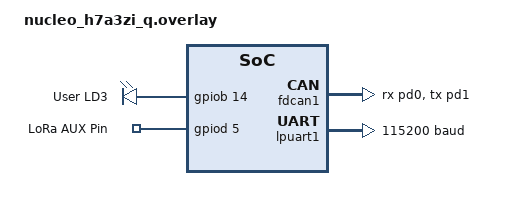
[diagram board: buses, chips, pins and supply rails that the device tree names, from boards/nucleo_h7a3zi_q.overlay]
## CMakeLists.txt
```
cmake_minimum_required(VERSION 3.20.0)

set(DTC_OVERLAY_FILE 
    "${CMAKE_CURRENT_LIST_DIR}/app.overlay"
    "${CMAKE_CURRENT_LIST_DIR}/boards/${BOARD}.overlay"
)

find_package(Zephyr REQUIRED HINTS $ENV{ZEPHYR_BASE})

project(deos_firmware)


target_sources(app PRIVATE
    src/main.cpp
    src/MainApp.cpp
    src/io/LedController.cpp
    src/io/SafetyManager.cpp
    src/io/ImuSensor.cpp
    src/network/NetworkMonitor.cpp
    src/transport/eth_textual.cpp
    src/transport/eth_ros_bridge.cpp
    src/transport/uart_lora.cpp
    ../../lib/deos_core/src/deos_core.c
    ../../lib/deos_core/src/deos_rx.c
    ../../lib/deos_core/src/deos_tx.c
    ../../lib/deos_core/src/deos_dispatch.c
    ../../lib/deos_core/src/deos_codec.c
    ../../lib/deos_core/src/deos_network.c
    ../../lib/deos_core/src/deos_router.c
    ../../lib/deos_core/src/deos_fault.c
)

zephyr_include_directories(../../lib/deos_core/include)

# Disable thread-safe statics for C++ to prevent __cxa_guard_* linker errors
target_compile_options(app PRIVATE $<$<COMPILE_LANGUAGE:CXX>:-fno-threadsafe-statics>)

# Disable thread-safe statics for C++ to prevent __cxa_guard_* linker errors
target_compile_options(app PRIVATE $<$<COMPILE_LANGUAGE:CXX>:-fno-threadsafe-statics>)
```

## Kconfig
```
source "Kconfig.zephyr"

rsource "../../lib/deos_core/Kconfig"
```

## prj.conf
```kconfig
# ============================================================
# Zephyr Project Configuration
# ============================================================

# Console / printk
CONFIG_PRINTK=y

# Assertions
CONFIG_ASSERT=y

# Logging
CONFIG_LOG=y
CONFIG_LOG_DEFAULT_LEVEL=3

# Main thread stack
CONFIG_MAIN_STACK_SIZE=2048

# ------------------------------------------------------------
# Add project-specific configuration below
# ------------------------------------------------------------

# ---------------------------------------------------------
# DEOS Core Prototype
# ---------------------------------------------------------

CONFIG_LOG=y
CONFIG_LOG_DEFAULT_LEVEL=3

# CAN desteği
CONFIG_CAN=y
CONFIG_CAN_FD_MODE=y

# ---------------------------------------------------------
# DEOS Core Configuration (Optional overrides)
# ---------------------------------------------------------
# CONFIG_DEOS_MAX_LOCAL_NODES=4
# CONFIG_DEOS_MAX_FAULT_RECORDS=32
# CONFIG_DEOS_MAX_HANDLERS=32
# CONFIG_DEOS_RX_QUEUE_SIZE=16
# CONFIG_DEOS_RX_THREAD_STACK_SIZE=1024
# CONFIG_DEOS_RX_THREAD_PRIORITY=5

# ---------------------------------------------------------
# LoRa UART & GPIO settings
# ---------------------------------------------------------
CONFIG_SERIAL=y
CONFIG_UART_INTERRUPT_DRIVEN=y
CONFIG_GPIO=y

# ---------------------------------------------------------
# CRC Support for LoRa
# ---------------------------------------------------------
CONFIG_CRC=y

# ---------------------------------------------------------
# Networking / Ethernet / TCP Sockets
# ---------------------------------------------------------
CONFIG_NETWORKING=y
CONFIG_NET_IPV4=y
CONFIG_NET_TCP=y
CONFIG_NET_UDP=y
CONFIG_NET_SOCKETS=y
# Maksimum bağlantı ve soket ayarları
CONFIG_NET_MAX_CONN=4
CONFIG_NET_MAX_CONTEXTS=4

# İsteğe bağlı Statik IP ayarı (Eğer DHCP yoksa)
# RPi tarafı ile aynı ağda (örn: 192.168.1.x) olmalıdır
CONFIG_NET_CONFIG_SETTINGS=y
CONFIG_NET_CONFIG_MY_IPV4_ADDR="192.168.1.10"
CONFIG_NET_CONFIG_PEER_IPV4_ADDR="192.168.1.1"

# Ethernet kablosu takılı değilse veya link gecikirse Zephyr'in bootta beklemesini engelle
CONFIG_NET_CONFIG_INIT_TIMEOUT=0
# ---------------------------------------------------------
# C++ Support
# ---------------------------------------------------------
CONFIG_CPP=y
CONFIG_STD_CPP17=y

# ---------------------------------------------------------
# micro-ROS Configuration (REMOVED)
# ---------------------------------------------------------
CONFIG_PICOLIBC=n
CONFIG_NEWLIB_LIBC=y

CONFIG_POSIX_API=y
```

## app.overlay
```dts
/*
 * ==============================================================================
 * ANA UYGULAMA OVERLAY DOSYASI (app.overlay)
 * ==============================================================================
 * Amacı: Bu dosya, uygulamanın donanımdan bağımsız "iskelet" yapısını kurar.
 * Hangi karta derlenirse derlensin her zaman geçerli olan ortak ayarları içerir.
 * Fiziksel pin atamaları BURADA YAPILMAZ! Pin atamaları 'boards/' klasöründeki
 * karta özel overlay dosyalarında yapılır.
 * ==============================================================================
 */

/ {
    chosen {
        zephyr,can-primary = &fdcan1;
    };
};

/* Enable Primary CAN (FDCAN1) */
&fdcan1 {
    status = "okay";
    bus-speed = <500000>;
    bus-speed-data = <2000000>;
};
```

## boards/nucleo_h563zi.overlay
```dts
/*
 * ==============================================================================
 * KARTA ÖZEL OVERLAY DOSYASI (boards/nucleo_h563zi.overlay)
 * ==============================================================================
 * Hedef Kart: NUCLEO-H563ZI (STM32H5)
 * Amacı: app.overlay dosyasında tanımlanan iskeletin (node ve alias'ların),
 * bu spesifik karta ait fiziksel pinlere ve donanımlara (UART, GPIO vb.) 
 * nasıl bağlanacağını (kablolanacağını) belirler.
 * ==============================================================================
 */

/ {
    aliases {
        lora-uart = &lpuart1;
        led2 = &red_led_1;
    };
};

/* CAN-FD Physical Pin Mapping */
&fdcan1 {
    pinctrl-0 = <&fdcan1_rx_pd0 &fdcan1_tx_pd1>;
    pinctrl-names = "default";
};

/* LoRa UART Physical Pin Mapping */
&lpuart1 {
    status = "okay";
    current-speed = <115200>;
    /* Note: H5 varsayılan olarak PB6(TX) ve PB7(RX) pinlerini kullanır */
};

/* LoRa AUX Physical Pin Mapping */
/ {
    lora_module {
        compatible = "gpio-keys";
        lora_aux: lora_aux {
            gpios = <&gpioe 14 GPIO_ACTIVE_HIGH>;
            label = "LoRa AUX Pin";
        };
    };
};
```

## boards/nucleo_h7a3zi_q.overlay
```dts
/*
 * ==============================================================================
 * KARTA ÖZEL OVERLAY DOSYASI (boards/nucleo_h7a3zi_q.overlay)
 * ==============================================================================
 * Hedef Kart: NUCLEO-H7A3ZI-Q (STM32H7)
 * Amacı: app.overlay dosyasında tanımlanan iskeletin (node ve alias'ların),
 * bu spesifik karta ait fiziksel pinlere ve donanımlara (UART, GPIO vb.) 
 * nasıl bağlanacağını (kablolanacağını) belirler.
 * ==============================================================================
 */

/ {
    aliases {
        lora-uart = &lpuart1;
        led2 = &my_red_led;
    };

    leds {
        compatible = "gpio-leds";
        my_red_led: led_2 {
            gpios = <&gpiob 14 GPIO_ACTIVE_HIGH>;
            label = "User LD3";
        };
    };
};

/* CAN-FD Physical Pin Mapping */
&fdcan1 {
    pinctrl-0 = <&fdcan1_rx_pd0 &fdcan1_tx_pd1>;
    pinctrl-names = "default";
};



/* LoRa UART Physical Pin Mapping */
&lpuart1 {
    status = "okay";
    current-speed = <115200>;
};

/* LoRa AUX Physical Pin Mapping */
/ {
    lora_module {
        compatible = "gpio-keys";
        lora_aux: lora_aux {
            gpios = <&gpiod 5 GPIO_ACTIVE_HIGH>;
            label = "LoRa AUX Pin";
        };
    };
};

&timers12 {
    status = "disabled";
};
```

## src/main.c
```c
#include <zephyr/kernel.h>
#include <zephyr/logging/log.h>
#include <deos/deos.h>
#include <deos/deos_fault.h>

#include "eth_textual.h"
#include "eth_uros.h"
#include "uart_lora.h"

LOG_MODULE_REGISTER(main_node, LOG_LEVEL_INF);

/* Application defined routing policy */
static deos_transport_t main_routing_policy(deos_node_id_t destination)
{
    if (destination == DEOS_NODE_TEXTUAL) {
        return DEOS_TRANSPORT_ETH_TEXTUAL;
    }
    if (destination == DEOS_NODE_MICRO_ROS) {
        return DEOS_TRANSPORT_ETH_UROS;
    }
    if (destination == DEOS_NODE_GROUND_CONTROL) {
        return DEOS_TRANSPORT_UART_LORA;
    }
    
    /* Route everything else to the CAN-FD network by default */
    return DEOS_TRANSPORT_CAN_FD;
}

int main(void)
{
    LOG_INF("Starting DEOS Main STM32 Gateway...");

    /* Initialize DEOS Configuration */
    struct deos_config config = {
        .node_id = DEOS_NODE_MAIN_STM32,
        .can_dev = DEVICE_DT_GET(DT_CHOSEN(zephyr_can_primary)),
        .router_enabled = true,
        .hosted_nodes_enabled = true
    };

    if (!device_is_ready(config.can_dev)) {
        LOG_ERR("CAN device not ready");
        return -1;
    }

    /* Set our custom routing lookup function */
    deos_router_set_lookup_fn(main_routing_policy);

    /* Initialize DEOS Core */
    int ret = deos_init(&config);
    if (ret != 0) {
        LOG_ERR("DEOS init failed: %d", ret);
        return ret;
    }

    /* Initialize External Ethernet Interfaces */
    eth_textual_init();
    eth_uros_init(); /* TODO: Implement micro-ROS */
    uart_lora_init();

    /* Start DEOS threads */
    deos_start();

    while (1) {
        k_sleep(K_MSEC(1000));
        /* Main application background tasks */
    }

    return 0;
}
```

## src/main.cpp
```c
#include "MainApp.hpp"

int main(void)
{
    if (MainApp::getInstance().init() == 0) {
        MainApp::getInstance().run();
    }
    return 0;
}
```

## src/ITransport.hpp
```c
#pragma once

#include <deos/deos.h>

class ITransport {
public:
    virtual ~ITransport() = default;
    
    /**
     * @brief Initialize the transport.
     * @return 0 on success, negative error code on failure.
     */
    virtual int init() = 0;
    
    /**
     * @brief Send a message over the transport.
     * @param msg Pointer to the DEOS message to send.
     * @return 0 on success, negative error code on failure.
     */
    virtual int send(const deos_message_t* msg) = 0;
};
```

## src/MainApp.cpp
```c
#include "MainApp.hpp"
#include "transport/eth_textual.hpp"
#include "transport/eth_ros_bridge.hpp"
#include "transport/uart_lora.hpp"
#include "io/ImuSensor.hpp"
#include <zephyr/logging/log.h>

LOG_MODULE_REGISTER(main_node_app, LOG_LEVEL_INF);

MainApp& MainApp::getInstance() {
    static MainApp instance;
    return instance;
}

static const char* state_to_str(deos_state_t s) {
    switch(s) {
        case DEOS_STATE_INIT: return "INIT (0x00)";
        case DEOS_STATE_STANDBY: return "STANDBY (0x01)";
        case DEOS_STATE_READY: return "READY (0x02)";
        case DEOS_STATE_ACTIVE: return "ACTIVE (0x03)";
        case DEOS_STATE_CALIBRATING: return "CALIBRATING (0x04)";
        case DEOS_STATE_SAFE: return "SAFE (0x05)";
        case DEOS_STATE_FAULT: return "FAULT (0x06)";
        default: return "UNKNOWN";
    }
}

extern "C" {
    int heartbeat_rx_callback(const deos_message_t *msg, void *user_data) {
        MainApp& app = MainApp::getInstance();
        
        deos_state_t reported_state = DEOS_STATE_UNKNOWN;
        if (msg->payload_len == sizeof(struct deos_heartbeat_payload)) {
            const struct deos_heartbeat_payload *pl = (const struct deos_heartbeat_payload *)msg->payload;
            reported_state = (deos_state_t)pl->current_state;
        }
        
        app.network_monitor.update_heartbeat(msg->source, reported_state, app.current_state);
        return 0;
    }

    int set_state_rx_callback(const deos_message_t *msg, void *user_data) {
        MainApp& app = MainApp::getInstance();
        
        if (msg->payload_len == 1) {
            deos_state_t req_state = (deos_state_t)msg->payload[0];
            LOG_INF("Received SET_STATE command from Node 0x%02X: requesting state %s", msg->source, state_to_str(req_state));
            app.set_state(req_state);
            deos_send_response(msg, DEOS_RESULT_SUCCESS, NULL, 0);
        } else {
            LOG_WRN("Invalid SET_STATE payload length: %d", msg->payload_len);
            deos_send_response(msg, DEOS_RESULT_INVALID_PARAMETER, NULL, 0);
        }
        return 0;
    }

    deos_transport_t c_routing_policy(deos_node_id_t destination) {
        if (destination == DEOS_NODE_GROUND_CONTROL) {
            return DEOS_TRANSPORT_UART_LORA;
        } else if (destination == DEOS_NODE_MICRO_ROS) {
            return DEOS_TRANSPORT_ETH_UROS;
        } else if (destination == DEOS_NODE_DIAG_TOOL) {
            return DEOS_TRANSPORT_ETH_TEXTUAL;
        }
        /* UART/LoRa testleri esnasinda CAN FD'ye gonderip sistemi kitlememesi icin kapali */
        /*
        else if (destination >= DEOS_NODE_TRACTION && destination <= DEOS_NODE_BMS_GATEWAY) {
            return DEOS_TRANSPORT_CAN_FD;
        }
        */
        return DEOS_TRANSPORT_LOCAL;
    }
}

int MainApp::init() {
    int ret = led_controller.init();
    if (ret != 0) return ret;

    ret = safety_manager.init();
    if (ret != 0) return ret;

    struct deos_config config = {
        .node_id = DEOS_NODE_MAIN_STM32,
        .can_dev = DEVICE_DT_GET(DT_CHOSEN(zephyr_can_primary)),
        .router_enabled = true,
        .hosted_nodes_enabled = true
    };

    if (!device_is_ready(config.can_dev)) {
        LOG_ERR("CAN device not ready");
        return -ENODEV;
    }

    ret = deos_init(&config);
    if (ret != 0) {
        LOG_ERR("DEOS init failed: %d", ret);
        return ret;
    }

    deos_router_set_lookup_fn(c_routing_policy);
    
    /* DEOS çekirdeğine Heartbeat paketlerini nereye düşüreceğini söylüyoruz */
    deos_register_handler(DEOS_CLASS_NETWORK, DEOS_SERVICE_SYSTEM, DEOS_CMD_SYSTEM_HEARTBEAT, heartbeat_rx_callback, NULL);

    /* SET_STATE komutunu (Cmd: 0x02, Class: COMMAND) dinle */
    deos_register_handler(DEOS_CLASS_COMMAND, DEOS_SERVICE_SYSTEM, DEOS_CMD_SYSTEM_SET_STATE, set_state_rx_callback, NULL);

    EthTextual::getInstance().init();
    EthRosBridge::getInstance().init();
    UartLora::getInstance().init();
    ImuSensor::getInstance().init();

    return 0;
}

void MainApp::set_state(deos_state_t new_state) {
    if (current_state == new_state) return;

    current_state = new_state;

    /* Durum değiştiğinde ağdaki tüm nodlara bildir (Broadcast) */
    deos_priority_t prio = (new_state == DEOS_STATE_SAFE || new_state == DEOS_STATE_FAULT) 
                            ? DEOS_PRIO_EMERGENCY : DEOS_PRIO_CONTROL;

    deos_send(DEOS_NODE_GLOBAL_BROADCAST, prio, DEOS_CLASS_COMMAND, DEOS_SERVICE_SYSTEM, 
              DEOS_CMD_SYSTEM_SET_STATE, &current_state, sizeof(current_state));

    LOG_INF("System State changed to: %s", state_to_str(current_state));
}

void MainApp::run() {
    deos_start();

    LOG_INF("Main System Controller (Brain) loop started.");

    /* Sistemi hazır (STANDBY) moduna geçir */
    set_state(DEOS_STATE_STANDBY);
    
    uint32_t ms_counter = 0;
    bool last_estop_state = safety_manager.is_estop_triggered();

    while (1) {
        bool estop_pressed = safety_manager.is_estop_triggered();

        /* --- DONANIMSAL KESME / GÜVENLİK KONTROLÜ (EDGE DETECTION) --- */
        if (estop_pressed && !last_estop_state) {
            LOG_ERR("!!! EMERGENCY STOP TRIGGERED !!!");
            set_state(DEOS_STATE_SAFE);
        } else if (!estop_pressed && last_estop_state) {
            LOG_INF("E-STOP Released.");
            set_state(DEOS_STATE_STANDBY);
        }
        
        last_estop_state = estop_pressed;

        /* --- NETWORK (NODE) WATCHDOG & HEARTBEAT --- */
        network_monitor.check_watchdog(*this);
        network_monitor.broadcast_heartbeat(current_state, ms_counter);

        /* --- STATE MACHINE (DURUM MAKİNESİ) Görselleri --- */
        led_controller.update(current_state, ms_counter);

        ms_counter += 10;
        k_sleep(K_MSEC(10));
    }
}
```

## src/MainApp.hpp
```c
#pragma once

#include <deos/deos.h>

class MainApp {
public:
    static MainApp& getInstance();
    
    int init();
    void run();

private:
    MainApp() = default;
    ~MainApp() = default;

    // Non-copyable
    MainApp(const MainApp&) = delete;
    MainApp& operator=(const MainApp&) = delete;

    static deos_transport_t routing_policy(deos_node_id_t destination);
};
```

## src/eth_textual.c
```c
#include <zephyr/kernel.h>
#include <zephyr/logging/log.h>
#include <zephyr/net/socket.h>
#include <deos/deos.h>
#include <deos/deos_fault.h>
#include "eth_textual.h"

LOG_MODULE_REGISTER(eth_textual, LOG_LEVEL_INF);

#define TEXTUAL_TX_QUEUE_SIZE 16
#define TEXTUAL_THREAD_STACK_SIZE 2048
#define TEXTUAL_THREAD_PRIO 5
#define TEXTUAL_TCP_PORT 5000

/* TX Queue to prevent blocking the router */
K_MSGQ_DEFINE(textual_tx_q, sizeof(deos_message_t), TEXTUAL_TX_QUEUE_SIZE, 4);

/* Threads */
static struct k_thread textual_server_thread_data;
static K_KERNEL_STACK_DEFINE(textual_server_stack, TEXTUAL_THREAD_STACK_SIZE);

static struct k_thread textual_tx_thread_data;
static K_KERNEL_STACK_DEFINE(textual_tx_stack, TEXTUAL_THREAD_STACK_SIZE);

/* Global client socket to allow TX thread to send data */
static int active_client_sock = -1;

/* Router TX callback */
static int textual_tx_callback(const deos_message_t *msg)
{
    /* If no client connected, just drop silently or log debug */
    if (active_client_sock < 0) {
        return -ENOTCONN;
    }

    /* Push to queue, do not block the router */
    if (k_msgq_put(&textual_tx_q, msg, K_NO_WAIT) != 0) {
        LOG_WRN("Textual TX queue full, dropping message");
        deos_fault_raise(DEOS_FAULT_TX_FAILURE, DEOS_FAULT_SEVERITY_WARNING);
        return -ENOSPC;
    }
    return 0;
}

/* TX Thread (Sends data out over TCP) */
static void textual_tx_thread(void *p1, void *p2, void *p3)
{
    deos_message_t msg;
    LOG_INF("Textual TCP TX Thread started");

    while (1) {
        if (k_msgq_get(&textual_tx_q, &msg, K_FOREVER) == 0) {
            if (active_client_sock >= 0) {
                /* Serialize to dynamic frame size */
                size_t header_sz = offsetof(deos_message_t, payload);
                uint8_t len = header_sz + msg.payload_len;
                
                uint8_t tx_buf[DEOS_MAX_PAYLOAD_LEN + 30];
                tx_buf[0] = len; /* 1 Byte Length */
                memcpy(&tx_buf[1], &msg, header_sz);
                if (msg.payload_len > 0) {
                    memcpy(&tx_buf[1 + header_sz], msg.payload, msg.payload_len);
                }

                /* Send over TCP */
                int sent = send(active_client_sock, tx_buf, len + 1, 0);
                if (sent < 0) {
                    LOG_ERR("TCP Send failed (%d), dropping client", errno);
                    close(active_client_sock);
                    active_client_sock = -1;
                }
            }
        }
    }
}

/* Server Thread (Listens for TCP and Receives data) */
static void textual_server_thread(void *p1, void *p2, void *p3)
{
    int serv_sock;
    struct sockaddr_in bind_addr;

    serv_sock = socket(AF_INET, SOCK_STREAM, IPPROTO_TCP);
    if (serv_sock < 0) {
        LOG_ERR("Failed to create TCP socket: %d", errno);
        return;
    }

    bind_addr.sin_family = AF_INET;
    bind_addr.sin_addr.s_addr = htonl(INADDR_ANY);
    bind_addr.sin_port = htons(TEXTUAL_TCP_PORT);

    if (bind(serv_sock, (struct sockaddr *)&bind_addr, sizeof(bind_addr)) < 0) {
        LOG_ERR("Failed to bind TCP socket: %d", errno);
        close(serv_sock);
        return;
    }

    if (listen(serv_sock, 1) < 0) {
        LOG_ERR("Failed to listen on TCP socket: %d", errno);
        close(serv_sock);
        return;
    }

    LOG_INF("Textual TCP Server listening on port %d", TEXTUAL_TCP_PORT);

    while (1) {
        struct sockaddr_in client_addr;
        socklen_t client_addr_len = sizeof(client_addr);
        
        LOG_INF("Waiting for Textual UI connection...");
        int client = accept(serv_sock, (struct sockaddr *)&client_addr, &client_addr_len);
        
        if (client < 0) {
            LOG_ERR("Accept failed: %d", errno);
            k_msleep(1000);
            continue;
        }

        LOG_INF("Textual UI Connected!");
        active_client_sock = client;

        while (1) {
            uint8_t rx_len;
            int ret = recv(client, &rx_len, 1, 0);
            if (ret <= 0) {
                LOG_INF("Textual UI Disconnected.");
                break;
            }

            /* Prevent buffer overflows */
            if (rx_len == 0 || rx_len > sizeof(deos_message_t)) {
                LOG_WRN("Invalid frame length %d received, closing connection.", rx_len);
                break;
            }

            uint8_t frame_buf[sizeof(deos_message_t)];
            int received = 0;
            
            /* Read exactly rx_len bytes for the frame */
            while (received < rx_len) {
                ret = recv(client, frame_buf + received, rx_len - received, 0);
                if (ret <= 0) break;
                received += ret;
            }

            if (received != rx_len) {
                LOG_WRN("Incomplete frame received.");
                break;
            }

            /* Successfully received full DEOS dynamic frame */
            size_t header_sz = offsetof(deos_message_t, payload);
            if (rx_len >= header_sz) {
                deos_message_t msg;
                memset(&msg, 0, sizeof(msg));
                memcpy(&msg, frame_buf, header_sz);
                msg.payload_len = rx_len - header_sz;
                
                if (msg.payload_len > 0) {
                    memcpy(msg.payload, frame_buf + header_sz, msg.payload_len);
                }
                
                /* Feed to router */
                deos_feed_message(&msg, DEOS_TRANSPORT_ETH_TEXTUAL);
            }
        }

        /* Clean up client connection */
        close(client);
        active_client_sock = -1;
    }
}

int eth_textual_init(void)
{
    /* Register this interface with the DEOS Router */
    deos_router_register_transport(DEOS_TRANSPORT_ETH_TEXTUAL, textual_tx_callback);

    /* Start the TX and RX/Server threads */
    k_thread_create(&textual_tx_thread_data, textual_tx_stack,
                    K_KERNEL_STACK_SIZEOF(textual_tx_stack),
                    textual_tx_thread, NULL, NULL, NULL,
                    TEXTUAL_THREAD_PRIO, 0, K_NO_WAIT);

    k_thread_create(&textual_server_thread_data, textual_server_stack,
                    K_KERNEL_STACK_SIZEOF(textual_server_stack),
                    textual_server_thread, NULL, NULL, NULL,
                    TEXTUAL_THREAD_PRIO, 0, K_NO_WAIT);

    LOG_INF("Textual Ethernet interface initialized");
    return 0;
}
```

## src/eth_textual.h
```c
#ifndef ETH_TEXTUAL_H
#define ETH_TEXTUAL_H

/**
 * @brief Initialize the Textual Ethernet interface and threads.
 */
int eth_textual_init(void);

#endif
```

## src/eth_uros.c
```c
#include <zephyr/kernel.h>
#include <zephyr/logging/log.h>
#include <deos/deos.h>
#include "eth_uros.h"

LOG_MODULE_REGISTER(eth_uros, LOG_LEVEL_INF);

/* 
 * TODO: micro-ROS integration is pending.
 * Similar to eth_textual.c, this will manage the connection to the 
 * micro-ROS agent or bridge ROS messages to DEOS frames.
 */

int eth_uros_init(void)
{
    /* TODO: Register transport and start threads when implemented */
    // deos_router_register_transport(DEOS_TRANSPORT_ETH_UROS, uros_tx_callback);
    
    LOG_INF("micro-ROS Ethernet interface initialized (TODO)");
    return 0;
}
```

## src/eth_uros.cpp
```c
#include "eth_uros.hpp"
#include <zephyr/logging/log.h>
#include <deos/deos.h>

LOG_MODULE_REGISTER(eth_uros, LOG_LEVEL_INF);

EthUros& EthUros::getInstance() {
    static EthUros instance;
    return instance;
}

int EthUros::tx_callback(const deos_message_t *msg) {
    return getInstance().send(msg);
}

int EthUros::send(const deos_message_t *msg) {
    // TODO: Implement micro-ROS message transmission logic here
    return 0;
}

int EthUros::init() {
    /* TODO: Register transport and start threads when implemented */
    // deos_router_register_transport(DEOS_TRANSPORT_ETH_UROS, tx_callback);
    
    LOG_INF("micro-ROS Ethernet interface initialized (OOP TODO)");
    return 0;
}
```

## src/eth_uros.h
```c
#ifndef ETH_UROS_H
#define ETH_UROS_H

/**
 * @brief Initialize the micro-ROS Ethernet interface.
 */
int eth_uros_init(void);

#endif
```

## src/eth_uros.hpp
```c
#pragma once

#include "ITransport.hpp"
#include <zephyr/kernel.h>

class EthUros : public ITransport {
public:
    static EthUros& getInstance();

    int init() override;
    int send(const deos_message_t* msg) override;

private:
    EthUros() = default;
    ~EthUros() = default;

    // Non-copyable
    EthUros(const EthUros&) = delete;
    EthUros& operator=(const EthUros&) = delete;

    static int tx_callback(const deos_message_t *msg);
};
```

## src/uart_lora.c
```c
#include <zephyr/kernel.h>
#include <zephyr/logging/log.h>
#include <zephyr/device.h>
#include <zephyr/drivers/uart.h>
#include <zephyr/drivers/gpio.h>
#include <zephyr/sys/ring_buffer.h>
#include <deos/deos.h>
#include <deos/deos_fault.h>
#include "uart_lora.h"

LOG_MODULE_REGISTER(uart_lora, LOG_LEVEL_INF);

#define LORA_TX_QUEUE_SIZE 16
#define LORA_THREAD_STACK_SIZE 1024
#define LORA_THREAD_PRIO 5

#define RING_BUF_SIZE 1024
RING_BUF_DECLARE(lora_rx_rb, RING_BUF_SIZE);

/* Threads and queues */
K_MSGQ_DEFINE(lora_tx_q, sizeof(deos_message_t), LORA_TX_QUEUE_SIZE, 4);

static struct k_thread lora_rx_thread_data;
static K_KERNEL_STACK_DEFINE(lora_rx_stack, LORA_THREAD_STACK_SIZE);

static struct k_thread lora_tx_thread_data;
static K_KERNEL_STACK_DEFINE(lora_tx_stack, LORA_THREAD_STACK_SIZE);

static const struct device *uart_dev = DEVICE_DT_GET(DT_ALIAS(lora_uart));

/* UART RX Interrupt Callback */
static void uart_rx_cb(const struct device *dev, void *user_data)
{
    uint8_t c;

    uart_irq_update(dev);

    if (uart_irq_rx_ready(dev)) {
        while (uart_fifo_read(dev, &c, 1) == 1) {
            if (ring_buf_put(&lora_rx_rb, &c, 1) == 0) {
                // Overflow (We can't safely raise DEOS fault in ISR)
            }
        }
    }
}

/* Router TX callback */
static int lora_tx_callback(const deos_message_t *msg)
{
    if (k_msgq_put(&lora_tx_q, msg, K_NO_WAIT) != 0) {
        LOG_WRN("LoRa TX queue full, dropping message");
        deos_fault_raise(DEOS_FAULT_TX_FAILURE, DEOS_FAULT_SEVERITY_WARNING);
        return -ENOSPC;
    }
    return 0;
}

/* Framing Constants */
#define LORA_MAGIC_1       0xAA
#define LORA_MAGIC_2       0x55
#define LORA_FLAG_NONE     0x00
#define LORA_FLAG_ACK_REQ  0x01
#define LORA_FLAG_IS_ACK   0x02
#define LORA_MAX_PAYLOAD   100

#include <zephyr/sys/crc.h>
#include <stddef.h>

/* Helper to send a frame (blocks in thread context) */
static void send_lora_frame(uint8_t flag, const uint8_t *payload, uint8_t len)
{
    uint8_t header[4] = { LORA_MAGIC_1, LORA_MAGIC_2, flag, len };
    uint16_t crc = crc16_ccitt(0xFFFF, &flag, 1);
    crc = crc16_ccitt(crc, &len, 1);
    if (len > 0) crc = crc16_ccitt(crc, payload, len);
    
    for(int i=0; i<4; i++) uart_poll_out(uart_dev, header[i]);
    for(int i=0; i<len; i++) uart_poll_out(uart_dev, payload[i]);
    uart_poll_out(uart_dev, crc & 0xFF);
    uart_poll_out(uart_dev, (crc >> 8) & 0xFF);
}

/* Helper to serialize and send DEOS message dynamically */
static void send_deos_lora(uint8_t flag, const deos_message_t *msg)
{
    size_t header_sz = offsetof(deos_message_t, payload);
    uint8_t buf[LORA_MAX_PAYLOAD];
    
    memcpy(buf, msg, header_sz);
    if (msg->payload_len > 0 && msg->payload_len <= DEOS_MAX_PAYLOAD_LEN) {
        memcpy(buf + header_sz, msg->payload, msg->payload_len);
    }
    
    uint8_t len = header_sz + msg->payload_len;
    send_lora_frame(flag, buf, len);
}

/* TX Thread (Sends data out over UART) */
static void lora_tx_thread(void *p1, void *p2, void *p3)
{
    deos_message_t msg;
    LOG_INF("LoRa TX Thread started with Dynamic Framing");

    while (1) {
        if (k_msgq_get(&lora_tx_q, &msg, K_FOREVER) == 0) {
            send_deos_lora(LORA_FLAG_NONE, &msg);
            LOG_DBG("LoRa TX: Sent framed message (Cmd: 0x%02X, Len: %d)", msg.command, msg.payload_len);
        }
    }
}

typedef enum {
    STATE_WAIT_MAGIC1, STATE_WAIT_MAGIC2,
    STATE_WAIT_FLAG, STATE_WAIT_LENGTH,
    STATE_WAIT_PAYLOAD, STATE_WAIT_CRC1, STATE_WAIT_CRC2
} rx_state_t;

/* RX Thread (Receives data from UART Ring Buffer) */
static void lora_rx_thread(void *p1, void *p2, void *p3)
{
    LOG_INF("LoRa RX Thread started with Framing and ACK Support!");
    
    rx_state_t rx_state = STATE_WAIT_MAGIC1;
    uint8_t rx_len = 0, rx_flag = 0;
    uint8_t rx_buf[LORA_MAX_PAYLOAD];
    int rx_idx = 0;
    uint16_t rx_crc = 0;

    while (1) {
        uint8_t c;
        if (ring_buf_get(&lora_rx_rb, &c, 1) == 1) {
            switch(rx_state) {
                case STATE_WAIT_MAGIC1:
                    if (c == LORA_MAGIC_1) rx_state = STATE_WAIT_MAGIC2;
                    break;
                case STATE_WAIT_MAGIC2:
                    if (c == LORA_MAGIC_2) rx_state = STATE_WAIT_FLAG;
                    else if (c != LORA_MAGIC_1) rx_state = STATE_WAIT_MAGIC1;
                    break;
                case STATE_WAIT_FLAG:
                    rx_flag = c;
                    rx_state = STATE_WAIT_LENGTH;
                    break;
                case STATE_WAIT_LENGTH:
                    rx_len = c;
                    rx_idx = 0;
                    if (rx_len > LORA_MAX_PAYLOAD) {
                        rx_state = STATE_WAIT_MAGIC1;
                    } else if (rx_len == 0) {
                        rx_state = STATE_WAIT_CRC1;
                    } else {
                        rx_state = STATE_WAIT_PAYLOAD;
                    }
                    break;
                case STATE_WAIT_PAYLOAD:
                    rx_buf[rx_idx++] = c;
                    if (rx_idx >= rx_len) rx_state = STATE_WAIT_CRC1;
                    break;
                case STATE_WAIT_CRC1:
                    rx_crc = c;
                    rx_state = STATE_WAIT_CRC2;
                    break;
                case STATE_WAIT_CRC2:
                    rx_crc |= (uint16_t)c << 8;
                    
                    uint16_t calc_crc = crc16_ccitt(0xFFFF, &rx_flag, 1);
                    calc_crc = crc16_ccitt(calc_crc, &rx_len, 1);
                    if (rx_len > 0) calc_crc = crc16_ccitt(calc_crc, rx_buf, rx_len);
                    
                    if (calc_crc == rx_crc) {
                        /* 1. Should we send ACK? */
                        if (rx_flag == LORA_FLAG_ACK_REQ) {
                            uint8_t ack_payload[2] = { calc_crc & 0xFF, (calc_crc >> 8) & 0xFF };
                            send_lora_frame(LORA_FLAG_IS_ACK, ack_payload, 2);
                            LOG_INF("uart_lora: Sent ACK for valid packet (CRC 0x%04X)", calc_crc);
                        }
                        
                        /* 2. Process data if it's not an ACK frame */
                        if (rx_flag != LORA_FLAG_IS_ACK) {
                            size_t header_sz = offsetof(deos_message_t, payload);
                            if (rx_len >= header_sz) {
                                deos_message_t msg;
                                memset(&msg, 0, sizeof(msg));
                                memcpy(&msg, rx_buf, header_sz);
                                msg.payload_len = rx_len - header_sz;
                                
                                if (msg.payload_len > 0 && msg.payload_len <= DEOS_MAX_PAYLOAD_LEN) {
                                    memcpy(msg.payload, rx_buf + header_sz, msg.payload_len);
                                }
                                
                                LOG_INF("uart_lora: RX SUCCESS (Dynamic, Len: %d)! Pushing Cmd: 0x%02X to Router...", msg.payload_len, msg.command);
                                deos_feed_message(&msg, DEOS_TRANSPORT_UART_LORA);
                            } else {
                                LOG_WRN("uart_lora: Received packet too small for DEOS Header!");
                            }
                        }
                    } else {
                        LOG_WRN("uart_lora: CRC mismatch! Calc: 0x%04X, Rx: 0x%04X", calc_crc, rx_crc);
                    }
                    rx_state = STATE_WAIT_MAGIC1;
                    break;
            }
        } else {
            k_msleep(1); /* Yield if ring buffer is empty */
        }
    }
}

int uart_lora_init(void)
{
    const struct device *gpiog = DEVICE_DT_GET(DT_NODELABEL(gpiog));
    const struct device *gpioe = DEVICE_DT_GET(DT_NODELABEL(gpioe));

    if (!device_is_ready(uart_dev)) {
        LOG_ERR("LoRa UART device not ready!");
        return -ENODEV;
    }

    if (device_is_ready(gpiog)) {
        gpio_pin_configure(gpiog, 14, GPIO_OUTPUT_INACTIVE); /* M0 (D2) -> LOW */
    } else {
        LOG_WRN("gpiog for M0 not ready");
    }

    if (device_is_ready(gpioe)) {
        gpio_pin_configure(gpioe, 13, GPIO_OUTPUT_INACTIVE); /* M1 (D3) -> LOW */
    } else {
        LOG_WRN("gpioe for M1 not ready");
    }

    /* Configure UART interrupt */
    uart_irq_callback_user_data_set(uart_dev, uart_rx_cb, NULL);
    uart_irq_rx_enable(uart_dev);

    /* Register interface with the DEOS Router */
    deos_router_register_transport(DEOS_TRANSPORT_UART_LORA, lora_tx_callback);

    /* Start the TX and RX threads */
    k_thread_create(&lora_tx_thread_data, lora_tx_stack,
                    K_KERNEL_STACK_SIZEOF(lora_tx_stack),
                    lora_tx_thread, NULL, NULL, NULL,
                    LORA_THREAD_PRIO, 0, K_NO_WAIT);

    k_thread_create(&lora_rx_thread_data, lora_rx_stack,
                    K_KERNEL_STACK_SIZEOF(lora_rx_stack),
                    lora_rx_thread, NULL, NULL, NULL,
                    LORA_THREAD_PRIO, 0, K_NO_WAIT);

    LOG_INF("LoRa UART interface initialized");
    return 0;
}
```

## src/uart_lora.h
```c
#ifndef UART_LORA_H
#define UART_LORA_H

/**
 * @brief Initialize the LoRa UART interface and threads.
 */
int uart_lora_init(void);

#endif
```
